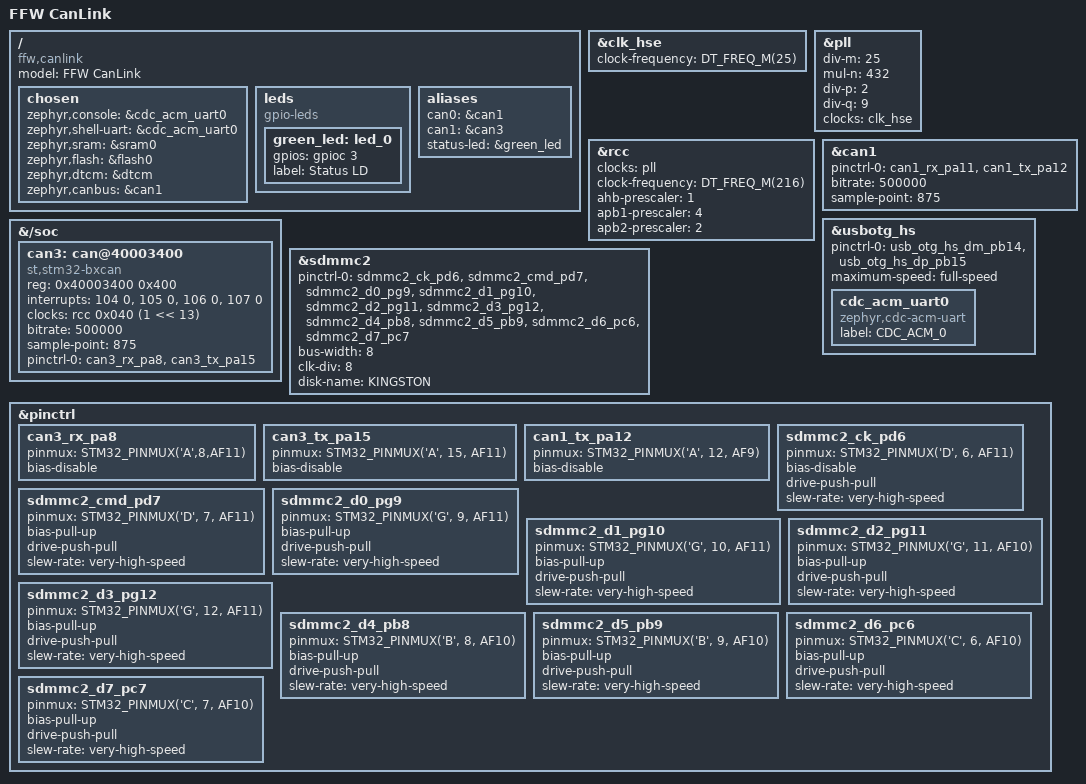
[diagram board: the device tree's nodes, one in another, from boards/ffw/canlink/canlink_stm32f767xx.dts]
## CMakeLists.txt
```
cmake_minimum_required(VERSION 3.20.0)

list(APPEND BOARD_ROOT ${CMAKE_CURRENT_SOURCE_DIR})

find_package(Zephyr REQUIRED HINTS ${ZEPHYR_BASE})
project(canlink)

target_sources(app PRIVATE
  src/duramax_build.cpp
  src/duramax_codec.cpp
  src/duramax_store.cpp
  src/duramax_validate.cpp
  src/reacher_build.cpp
  src/reacher_store.cpp
  src/reacher_codec.cpp
  src/reacher_validate.cpp
  src/main.cpp
  src/can_diagnostics.cpp
)

target_include_directories(app PRIVATE
  include
)
```

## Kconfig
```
mainmenu "CANLink"
source "Kconfig.zephyr"
menu "CANLink diagnostics"
config CANLINK_DIAGNOSTICS
    bool
    default y
    select STATS
    select CAN_STATS
    select CAN_MANUAL_RECOVERY_MODE
    select HWINFO if SOC_FAMILY_STM32
config CANLINK_EVENT_QUEUE_DEPTH
    int "ISR bus-event queue depth per bus"
    default 32
    range 4 256
config CANLINK_LOG_DEPTH
    int "Retained event records per boot per bus"
    default 64
    range 8 512
config CANLINK_TX_CONTEXTS
    int "Outstanding TX callback contexts per bus"
    default 8
    range 3 64
config CANLINK_RECOVERY_INITIAL_MS
    int "First failed recovery retry delay (ms)"
    default 100
    range 1 60000
config CANLINK_RECOVERY_MAX_MS
    int "Maximum failed recovery retry delay (ms)"
    default 5000
    range 1 600000
config CANLINK_RECOVERY_CONFIRM_MS
    int "Recovery completion observation interval (ms)"
    default 100
    range 1 60000
config CANLINK_DIAGNOSTIC_POLL_MS
    int "State/statistics reconciliation period (ms)"
    default 50
    range 1 60000
config CANLINK_RECOVERY_STACK_SIZE
    int "Recovery executor stack per bus"
    default 2048
    range 1024 16384
config CANLINK_RAW_FRAME_DEPTH
    int "Last raw RX/accepted-TX frames (0 disables)"
    default 0
    range 0 128
config CANLINK_SUPPRESS_UNHEALTHY_TX
    bool "Suppress TX before hooks while bus-off or stopped"
    default y
config CANLINK_RETAIN_DTCM
    bool "Use uncached DTCM noinit for retained banks"
    default y if SOC_SERIES_STM32F7X
    depends on DT_HAS_ARM_DTCM_ENABLED
endmenu

menu "CANLink throttle TX policy"
config CANLINK_THROTTLE_BAND_MAPPING
    bool "Apply legacy 1250/2000 RPM throttle bands"
    default y
    help
      Disable to pass the validated raw request through unchanged. Startup and
      stale-command gating still apply, including to a valid zero request.
config CANLINK_THROTTLE_STALE_TIMEOUT_ENABLE
    bool "Disable override when Reacher throttle input is stale"
    default y
config CANLINK_THROTTLE_STALE_TIMEOUT_MS
    int "Maximum age of a valid Reacher throttle command (ms)"
    default 500
    range 1 2147483647
choice CANLINK_THROTTLE_STALE_FALLBACK
    prompt "Stale throttle fallback"
    default CANLINK_THROTTLE_STALE_OVERRIDE_DISABLED
config CANLINK_THROTTLE_STALE_OVERRIDE_DISABLED
    bool "Override disabled, requested speed zero"
endchoice
endmenu
```

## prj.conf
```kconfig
CONFIG_GPIO=y
#CONFIG_SERIAL=y
CONFIG_CONSOLE=y
CONFIG_UART_CONSOLE=y
CONFIG_CPP=y
CONFIG_GLIBCXX_LIBCPP=y
CONFIG_STD_CPP23=y
CONFIG_CAN=y


CONFIG_POLL=y
CONFIG_ZBUS=y
```

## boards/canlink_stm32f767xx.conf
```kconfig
CONFIG_USB_DC_STM32_CLOCK_CHECK=n
CONFIG_SDMMC_STM32_CLOCK_CHECK=n



CONFIG_SERIAL=y
CONFIG_CONSOLE=y
CONFIG_UART_CONSOLE=y
CONFIG_STDOUT_CONSOLE=y
CONFIG_UART_LINE_CTRL=y

CONFIG_USB_DEVICE_STACK=y
CONFIG_USB_CDC_ACM=y
CONFIG_USB_DEVICE_INITIALIZE_AT_BOOT=y
CONFIG_USB_DEVICE_STACK_NEXT=n
#CONFIG_USBD_CDC_ACM_CLASS=y

#CONFIG_CDC_ACM_SERIAL_INITIALIZE_AT_BOOT=y
#CONFIG_CDC_ACM_SERIAL_PID=0x0004
#CONFIG_CDC_ACM_SERIAL_PRODUCT_STRING="CanLink USB console"

CONFIG_DEBUG_THREAD_INFO=y
CONFIG_FAULT_DUMP=2

CONFIG_INIT_STACKS=y
CONFIG_THREAD_STACK_INFO=y
CONFIG_STACK_SENTINEL=y
CONFIG_STACK_USAGE=y

CONFIG_MAIN_STACK_SIZE=32768


CONFIG_SDMMC_STM32_EMMC=y


CONFIG_MMC_STACK=y
CONFIG_DISK_ACCESS=y
CONFIG_DISK_DRIVER_SDMMC=y
CONFIG_SDMMC_STM32=y

CONFIG_FILE_SYSTEM=y
CONFIG_FAT_FILESYSTEM_ELM=y
CONFIG_FS_FATFS_LFN=y

CONFIG_LOG=y
CONFIG_PRINTK=y


CONFIG_CACHE_MANAGEMENT=y
CONFIG_DCACHE=y
# Explicit throttle defaults; set BAND_MAPPING=n for exact raw pass-through.
CONFIG_CANLINK_THROTTLE_BAND_MAPPING=y
CONFIG_CANLINK_THROTTLE_STALE_TIMEOUT_ENABLE=y
CONFIG_CANLINK_THROTTLE_STALE_TIMEOUT_MS=500
CONFIG_CANLINK_THROTTLE_STALE_OVERRIDE_DISABLED=y
```

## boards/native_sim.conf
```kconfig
CONFIG_CAN=y
CONFIG_CAN_NATIVE_LINUX=y

CONFIG_CPP=y
CONFIG_STD_CPP23=y

CONFIG_EXTERNAL_LIBC=y
CONFIG_EXTERNAL_LIBCPP=y

CONFIG_SERIAL=y
CONFIG_CONSOLE=y
CONFIG_UART_CONSOLE=y
CONFIG_PRINTK=y

CONFIG_SHELL=y
CONFIG_SHELL_BACKEND_SERIAL=y


CONFIG_POLL=y
CONFIG_DEBUG=y
CONFIG_NO_OPTIMIZATIONS=y

CONFIG_SYS_CLOCK_TICKS_PER_SEC=1000


CONFIG_MAIN_THREAD_PRIORITY=10
# Explicit throttle defaults; set BAND_MAPPING=n for exact raw pass-through.
CONFIG_CANLINK_THROTTLE_BAND_MAPPING=y
CONFIG_CANLINK_THROTTLE_STALE_TIMEOUT_ENABLE=y
CONFIG_CANLINK_THROTTLE_STALE_TIMEOUT_MS=500
CONFIG_CANLINK_THROTTLE_STALE_OVERRIDE_DISABLED=y
```

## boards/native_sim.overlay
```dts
/ {
	chosen {
		zephyr,canbus = &can0;
		zephyr,console = &uart0;
		zephyr,shell-uart = &uart0;
	};

	aliases {
		can0 = &can0;
		can1 = &can1_sim;
		status-led = &led0;
	};

	can1_sim: can1 {
		compatible = "zephyr,native-linux-can";
		status = "okay";
		host-interface = "vcan1";
		bitrate = <500000>;
		sample-point = <875>;
	};
};

&can0 {
	status = "okay";
	host-interface = "vcan0";
	bitrate = <500000>;
	sample-point = <875>;
};


&uart0 {
	status="okay";
	current-speed=<115200>;
};
```

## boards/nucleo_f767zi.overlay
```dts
&{/} {
    chosen {
        zephyr,console = &usart3;
        zephyr,shell-uart = &usart3;
        zephyr,sram = &sram0;
        zephyr,flash = &flash0;
    };

    aliases {
        can0 = &can1;
        can1 = &can3;
    };

};


&{/soc}{
    can2: can@40006800 { 

        compatible = "st,stm32-bxcan"; 

        reg = <0x40006800 0x400>; 
        interrupts = <63 0>, <64 0>, <65 0>, <66 0>; 
        interrupt-names = "TX", "RX0", "RX1", "SCE"; 
        clocks = <&rcc 0x040 (1 << 26)>; 
        status = "okay"; 
        bitrate = <500000>; 
        sample-point = <875>; 
        pinctrl-0 = <&can2_rx_pb12 &can2_tx_pb13>; 
        pinctrl-names = "default"; 
    };
    
    can3: can@40003400 {
        compatible = "st,stm32-bxcan";
        
        reg = <0x40003400 0x400>;
        interrupts = <104 0>, <105 0>, <106 0>, <107 0>;
        interrupt-names = "TX", "RX0", "RX1", "SCE";
        clocks = <&rcc 0x040 (1 << 13)>;
        status = "okay";
        bitrate = <500000>;
        sample-point = <875>;
        pinctrl-0 = <&can3_rx_pa8 &can3_tx_pa15>;
        pinctrl-names = "default";
    };


};

&can1 {
    status = "okay";
    pinctrl-0 = <&can1_rx_pa11 &can1_tx_pa12>;
    pinctrl-names = "default";
    bitrate = <500000>;
    sample-point = <875>;

};

&can3 {
    status = "okay";
    pinctrl-0 = <&can3_rx_pa8 &can3_tx_pa15>;
    pinctrl-names = "default";
};
 

&pinctrl { 
    can1_tx_pa12: can1_tx_pa12 { pinmux = <STM32_PINMUX('A', 12, AF9)>; bias-disable; };
    can2_tx_pb13: can2_tx_pb13 { pinmux = <STM32_PINMUX('B', 13, AF9)>; bias-disable; }; 
    can3_rx_pa8:  can3_rx_pa8  { pinmux = <STM32_PINMUX('A',8,AF11)>; bias-disable; };
    can3_tx_pa15: can3_tx_pa15 { pinmux = <STM32_PINMUX('A', 15, AF11)>; bias-disable; };
    can2_rx_pb12: can2_rx_pb12 { pinmux = <STM32_PINMUX('B', 12, AF9)>; bias-disable; }; 


}; 
```

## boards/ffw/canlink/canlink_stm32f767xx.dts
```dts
/dts-v1/;
#include <st/f7/stm32f767Xi.dtsi>
#include <st/f7/stm32f767zitx-pinctrl.dtsi>

/ {

    model = "FFW CanLink";
    compatible = "ffw,canlink";

    chosen {
        zephyr,console = &cdc_acm_uart0;
        zephyr,shell-uart = &cdc_acm_uart0;
        zephyr,sram = &sram0;
        zephyr,flash = &flash0;
        zephyr,dtcm = &dtcm;
        zephyr,canbus = &can1;
    };

    leds: leds {
        compatible = "gpio-leds";
        green_led: led_0 {
            gpios = <&gpioc 3 GPIO_ACTIVE_HIGH>;
            label = "Status LD";
        };
    };

    aliases {
        can0 = &can1;
        can1 = &can3;
        status-led = &green_led;
    };

};


/* now on to editing some nodes (reference zephyr/boards/st/nucleo_f767zi.dts ) */

&clk_hse {
    clock-frequency = <DT_FREQ_M(25)>;
    status = "okay";
};


&pll {
    div-m = <25>;
    mul-n = <432>;
    div-p = <2>;
    div-q = <9>;
    clocks = <&clk_hse>;
    status = "okay";
};

&rcc { 
    clocks = <&pll>;
    clock-frequency = <DT_FREQ_M(216)>;
    ahb-prescaler = <1>;
    apb1-prescaler = <4>;
    apb2-prescaler = <2>;
};

&{/soc}{
    
    can3: can@40003400 {
        compatible = "st,stm32-bxcan";
        
        reg = <0x40003400 0x400>;
        interrupts = <104 0>, <105 0>, <106 0>, <107 0>;
        interrupt-names = "TX", "RX0", "RX1", "SCE";
        clocks = <&rcc 0x040 (1 << 13)>;
        status = "okay";
        bitrate = <500000>;
        sample-point = <875>;
        pinctrl-0 = <&can3_rx_pa8 &can3_tx_pa15>;
        pinctrl-names = "default";
    };

};


&can1 {
    status = "okay";
    pinctrl-0 = <&can1_rx_pa11 &can1_tx_pa12>;
    pinctrl-names = "default";
    bitrate = <500000>;
    sample-point = <875>;

};

&can3 {
    status = "okay";
    pinctrl-0 = <&can3_rx_pa8 &can3_tx_pa15>;
    pinctrl-names = "default";
};

zephyr_udc0: &usbotg_hs {
	pinctrl-0 = <&usb_otg_hs_dm_pb14 &usb_otg_hs_dp_pb15>;
	pinctrl-names = "default";
	status = "okay";
    maximum-speed = "full-speed";

	cdc_acm_uart0: cdc_acm_uart0 {
		compatible = "zephyr,cdc-acm-uart";
        label = "CDC_ACM_0";
	};
};

&sdmmc2 {
    status = "okay";
    pinctrl-0 = <&sdmmc2_ck_pd6
                 &sdmmc2_cmd_pd7 
                 &sdmmc2_d0_pg9
                 &sdmmc2_d1_pg10
                 &sdmmc2_d2_pg11
                 &sdmmc2_d3_pg12
                 &sdmmc2_d4_pb8
                 &sdmmc2_d5_pb9
                 &sdmmc2_d6_pc6
                 &sdmmc2_d7_pc7>;
    pinctrl-names = "default";

    bus-width = <8>;
    clk-div = <8>;

    disk-name = "KINGSTON";

};

&pinctrl{

    can3_rx_pa8:  can3_rx_pa8  { pinmux = <STM32_PINMUX('A',8,AF11)>;    bias-disable; };
    can3_tx_pa15: can3_tx_pa15 { pinmux = <STM32_PINMUX('A', 15, AF11)>; bias-disable; };

    can1_tx_pa12: can1_tx_pa12 { pinmux = <STM32_PINMUX('A', 12, AF9)>;  bias-disable; };

    sdmmc2_ck_pd6: sdmmc2_ck_pd6 {
        pinmux = <STM32_PINMUX('D', 6, AF11)>;
        bias-disable;
        drive-push-pull;
        slew-rate = "very-high-speed";
    };

    sdmmc2_cmd_pd7: sdmmc2_cmd_pd7 {
        pinmux = <STM32_PINMUX('D', 7, AF11)>;
        bias-pull-up;
        drive-push-pull;
        slew-rate = "very-high-speed";
    };

    sdmmc2_d0_pg9: sdmmc2_d0_pg9 {
        pinmux = <STM32_PINMUX('G', 9, AF11)>;
        bias-pull-up;
        drive-push-pull;
        slew-rate = "very-high-speed";
    };

    sdmmc2_d1_pg10: sdmmc2_d1_pg10 {
        pinmux = <STM32_PINMUX('G', 10, AF11)>;
        bias-pull-up;
        drive-push-pull;
        slew-rate = "very-high-speed";
    };

    sdmmc2_d2_pg11: sdmmc2_d2_pg11 {
        pinmux = <STM32_PINMUX('G', 11, AF10)>;
        bias-pull-up;
        drive-push-pull;
        slew-rate = "very-high-speed";
    };

    sdmmc2_d3_pg12: sdmmc2_d3_pg12 {
        pinmux = <STM32_PINMUX('G', 12, AF11)>;
        bias-pull-up;
        drive-push-pull;
        slew-rate = "very-high-speed";
    };

    sdmmc2_d4_pb8: sdmmc2_d4_pb8 {
        pinmux = <STM32_PINMUX('B', 8, AF10)>;
        bias-pull-up;
        drive-push-pull;
        slew-rate = "very-high-speed";
    };

    sdmmc2_d5_pb9: sdmmc2_d5_pb9 {
        pinmux = <STM32_PINMUX('B', 9, AF10)>;
        bias-pull-up;
        drive-push-pull;
        slew-rate = "very-high-speed";
    };

    sdmmc2_d6_pc6: sdmmc2_d6_pc6 {
        pinmux = <STM32_PINMUX('C', 6, AF10)>;
        bias-pull-up;
        drive-push-pull;
        slew-rate = "very-high-speed";
    };

    sdmmc2_d7_pc7: sdmmc2_d7_pc7 {
        pinmux = <STM32_PINMUX('C', 7, AF10)>;
        bias-pull-up;
        drive-push-pull;
        slew-rate = "very-high-speed";
    };
};
```

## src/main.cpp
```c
#include <zephyr/device.h>
#include <zephyr/devicetree.h>
#include <zephyr/kernel.h>
#include <zephyr/sys/printk.h>
#include <zephyr/drivers/gpio.h>
#include <zephyr/drivers/uart.h>
#include <zephyr/drivers/disk.h>

#include <zephyr/usb/usb_device.h>

#include <zephyr/storage/disk_access.h>

#include <tuple>
#include <utility>
#include <string.h>

#include <zephyr/app_version.h>

#include "can_active_object.hpp"
#include "can_endpoint.hpp"

#include "duramax/duramax_db.hpp"
#include "duramax/duramax_hooks.hpp"
#include "duramax/duramax_choices.hpp"

#include "reacher/reacher_db.hpp"
#include "reacher/reacher_hooks.hpp"

#include "translator_active_object.hpp"
#include "duramax_to_reacher_signal_table.hpp"
#include "reacher_to_duramax_signal_table.hpp"
#include "message_policy_table.hpp"

namespace {
#define MY_LED_NODE DT_ALIAS(status_led)

using DuramaxAo = canfw::CanActiveObject<duramax::DuramaxDb, DuramaxHooks>;
using ReacherAo = canfw::CanActiveObject<reacher::ReacherDb, ReacherHooks>;

using DuramaxToReacherTranslator =
    Translator<
        duramax::DuramaxDb,
        reacher::ReacherDb,
        DuramaxToReacherTranslations<duramax::DuramaxDb, reacher::ReacherDb>
    >;

using ReacherToDuramaxTranslator =
    Translator<
        reacher::ReacherDb,
        duramax::DuramaxDb,
        ReacherToDuramaxTranslations<reacher::ReacherDb, duramax::DuramaxDb>
    >;

const device* const dm_bus = DEVICE_DT_GET(DT_ALIAS(can0));
const device* const reacher_bus = DEVICE_DT_GET(DT_ALIAS(can1));

static const struct gpio_dt_spec led = GPIO_DT_SPEC_GET(MY_LED_NODE, gpios);

// Stats print every Nth 100 ms iteration. Main runs at a higher priority
// than the AO threads by default (CONFIG_MAIN_THREAD_PRIORITY=0 vs 5), and
// synchronous printk spin-polls the UART, so every character printed here
// is time stolen from the 10 ms TSC1 schedule. Printing at 2 s instead of
// 100 ms cuts that starvation twentyfold; the real fix (deferred logging +
// priority inversion) is tracked for Phase 1.
constexpr std::uint8_t kStatsDivider = 20;

template <typename Endpoint, typename Msg>
void enable_periodic_checked(const Endpoint& ep,
                             const Msg& msg,
                             std::uint32_t period_ms,
                             const char* name)
{
    const int rc = ep.enable_periodic(msg, period_ms);
    if (rc != 0) {
        printk("enable_periodic(%s) failed: %d\n", name, rc);
    }
}

} // namespace

// eMMC bring-up scaffolding, kept for bench use. Not called from main():
// it never returns, which left the entire CAN path below unreachable.
int fake_main(){
    static int counter = 0;
    const char *disk = "KINGSTON";

    int rc = disk_access_ioctl(disk, DISK_IOCTL_CTRL_INIT, NULL);
    printk("disk_access_init(%s) = %d\n", disk, rc);

    uint32_t sector_count = 0;
    uint32_t sector_size = 0;

    rc = disk_access_ioctl(disk, DISK_IOCTL_GET_SECTOR_COUNT, &sector_count);
    printk("sector_count rc=%d count=%u\n", rc, sector_count);

    rc = disk_access_ioctl(disk, DISK_IOCTL_GET_SECTOR_SIZE, &sector_size);
    printk("sector_size rc=%d size=%u\n", rc, sector_size);

    __aligned(32) static uint8_t write_buf[512];
    __aligned(32) static uint8_t read_buf[512];

    if (sector_size > sizeof(write_buf)){
        printk("Sector size too large for test buffer\n");
        return -1;
    }

    // returned a value that indicates this ioctl command returned no useful data...
    // fudge...
    uint32_t erase_block_size = 0;
    rc = disk_access_ioctl(disk, DISK_IOCTL_GET_ERASE_BLOCK_SZ, &erase_block_size);
    printk("erase block size rc=%d, size=%u\n", rc, erase_block_size);


    uint32_t id = 0;
    rc = disk_access_ioctl(disk, DISK_IOCTL_GET_CARD_CID, &id);
    printk("disk cid:: rc=%d, id=%u\n", rc, id);

    memset(write_buf, 0x00, sizeof(write_buf));
    memset(read_buf, 0x00, sizeof(read_buf));

    // const char *msg = "CANLINK EMMC TEST V1";

    // memcpy(write_buf, msg, strlen(msg) + 1);

     uint32_t test_sector = 128;
    // rc = disk_access_write(disk, write_buf, test_sector, 1);

    // printk("WRITE rc=%d\n", rc);
    // if (rc){
    //     return rc;
    // }

    rc = disk_access_ioctl(disk, DISK_IOCTL_CTRL_SYNC, NULL);

    printk("SYNC rc=%d\n", rc);
    if(rc){
        return rc;
    }

    printk("about to READ\n");
    rc = disk_access_read(disk, read_buf, test_sector, 1);

    printk("READ rc=%d", rc);
    if (rc){
        return rc;
    }

    printk("READBACK: %s\n", read_buf);

    while (1) {
        k_sleep(K_SECONDS(1));
        if (counter > 5){
            printk("stuck in the loop!\n");
        }
        counter = (counter + 1) % 6;
    }
}

int main(void)
{
    const struct device *const dev = DEVICE_DT_GET(DT_CHOSEN(zephyr_console));
    if (!device_is_ready(dev)){
        printk("console not ready\n");
        return -1;
    }

    // DISABLED SECTION DUE TO KCONFIG 
    // CONFIG_USB_DEVICE_INITIALIZE_AT_BOOT=y
    // int ret = usb_enable(NULL);

    // if (ret != 0){
    //     printk("usb_enable failed: %d\n", ret);
    //     return -1;
    // }


    k_sleep(K_SECONDS(1));

    // To run the eMMC bench test instead of the CAN gateway:
    //return fake_main();

    auto duramax_result = DuramaxAo::create(dm_bus, DuramaxHooks{}, true);
    if (!duramax_result) {
        printk("DuramaxAo init failed: %d\n", static_cast<int>(duramax_result.error()));
        return -1;
    }

    auto reacher_result = ReacherAo::create(reacher_bus, ReacherHooks{}, false);
    if (!reacher_result) {
        printk("ReacherAo init failed: %d\n", static_cast<int>(reacher_result.error()));
        return -1;
    }

    auto* duramax_ao = *duramax_result;
    auto* reacher_ao = *reacher_result;

    auto duramax_ep = duramax_ao->endpoint();
    auto reacher_ep = reacher_ao->endpoint();

    if (!duramax_ep.valid() || !reacher_ep.valid()) {
        printk("Endpoint invalid\n");
        return -1;
    }

    // Seed periodic Reacher export messages.
    //
    // The k_sleep between enables is deliberate phase staggering: a freshly
    // enabled message is due immediately, and the fixed-rate scheduler then
    // holds that phase forever. Enabling all four in one command batch put
    // them on the SAME 50 ms phase, so every cycle they hit can_send at the
    // same instant -- with K_NO_WAIT mailbox acquisition, only the first
    // wins and the rest count as tx_send_failures (observed ~50/s on
    // native_sim). A few ms of offset spreads the grid points apart for good.
    {
        reacher::Export0 export0{};
        export0.eng_speed = 0;
        export0.actual_throttle = 0.0;
        export0.manifold_press = 0;
        enable_periodic_checked(reacher_ep, export0, 50, "export0");
        k_sleep(K_MSEC(2));

        reacher::Export3 export3{};
        export3.fuel_rail_pressure = 0;
        enable_periodic_checked(reacher_ep, export3, 50, "export3");
        k_sleep(K_MSEC(3));

        reacher::Export8 export8{};
        export8.battery_bus_voltage = 0.0;
        enable_periodic_checked(reacher_ep, export8, 100, "export8");
        k_sleep(K_MSEC(2));

        reacher::ExportB exportb{};
        exportb.coolant_temp = 50.0;
        exportb.oil_temp = 0.0;
        exportb.oil_pressure = 0.0;
        exportb.exhaust_gas_temp = 0.0;
        enable_periodic_checked(reacher_ep, exportb, 50, "exportb");
    }

    // Seed periodic Duramax TSC1
    {
        duramax::Tsc131 tsc1{};
        tsc1.engoverridectrlmode = 0;
        tsc1.engrequestedspeedctrlconditions = 0;
        tsc1.overridectrlmodepriority = 0;
        tsc1.engrequestedspeed_speedlimit = 0.0;
        tsc1.engrequestedtorque_torquelimit = -125;
        tsc1.tsc1transrate = std::to_underlying(
            duramax::Tsc131Tsc1transrateState::use_standard_tsc1_transmission_rates_of_10_ms_to_engine);
        tsc1.tsc1ctrlpurpose = 0;
        tsc1.engrequestedtorquehighresolution = 0;
        tsc1.messagecounter = 0;
        tsc1.messagechecksum = 0;

        if (auto ok = duramax::DuramaxDb::validate_message(tsc1); !ok) {
            printk("Initial TSC1 validation failed: signal=%u error=%u\n",
                   static_cast<unsigned>(duramax::DuramaxDb::to_index(ok.error().signal_id)),
                   static_cast<unsigned>(ok.error().error));
            return -1;
        }

        enable_periodic_checked(duramax_ep, tsc1, 10, "tsc1");
    }

    // Static storage duration is mandatory: each Translator owns two
    // SnapshotReply-sized buffers (~14 KB for the Duramax direction). As
    // function locals these overflowed the main stack; as function-local
    // statics they live in .bss and are still constructed here, after the
    // endpoints exist. -Wframe-larger-than guards against regression.
    static DuramaxToReacherTranslator duramax_to_reacher{duramax_ep, reacher_ep};
    static ReacherToDuramaxTranslator reacher_to_duramax{reacher_ep, duramax_ep};

    if (!duramax_to_reacher.valid() || !reacher_to_duramax.valid()) {
        printk("Translator invalid\n");
        return -1;
    }

    if(!gpio_is_ready_dt(&led)){
        return -1;
    }

    gpio_pin_configure_dt(&led, GPIO_OUTPUT_ACTIVE);
    static uint8_t num = 0;
    static uint8_t stats_div = 0;

    while (true) {
        duramax_to_reacher.step_once();
        reacher_to_duramax.step_once();

        if (stats_div == 0) {
            printk("D->R posted=%u val_fail=%u upd_fail=%u src_missing=%u snap_fail=%u\n",
                   duramax_to_reacher.updates_posted(),
                   duramax_to_reacher.validation_failures(),
                   duramax_to_reacher.update_failures(),
                   duramax_to_reacher.source_missing_count(),
                   duramax_to_reacher.snapshot_failures());

            printk("R->D posted=%u val_fail=%u upd_fail=%u src_missing=%u snap_fail=%u\n",
                   reacher_to_duramax.updates_posted(),
                   reacher_to_duramax.validation_failures(),
                   reacher_to_duramax.update_failures(),
                   reacher_to_duramax.source_missing_count(),
                   reacher_to_duramax.snapshot_failures());

            printk("duramax sent=%u decode_fail=%u build_fail=%u encode_fail=%u val_fail=%u send_fail=%u sched_fail=%u\n",
                   duramax_ao->tx_frames_sent(),
                   duramax_ao->decode_failures(),
                   duramax_ao->tx_build_failures(),
                   duramax_ao->tx_encode_failures(),
                   duramax_ao->tx_validation_failures(),
                   duramax_ao->tx_send_failures(),
                   duramax_ao->tx_schedule_failures());

            printk("reacher sent=%u decode_fail=%u build_fail=%u encode_fail=%u val_fail=%u send_fail=%u sched_fail=%u\n",
                   reacher_ao->tx_frames_sent(),
                   reacher_ao->decode_failures(),
                   reacher_ao->tx_build_failures(),
                   reacher_ao->tx_encode_failures(),
                   reacher_ao->tx_validation_failures(),
                   reacher_ao->tx_send_failures(),
                   reacher_ao->tx_schedule_failures());
        }
        stats_div = (stats_div + 1) % kStatsDivider;

        if(num == 0){
            gpio_pin_toggle_dt(&led);
        }
        num = (num + 1) % 17;

        k_sleep(K_MSEC(100));
    }

    return 0;
}
```

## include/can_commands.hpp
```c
#pragma once

#include <zephyr/kernel.h>

#include <cstdint>
#include <variant>
#include "throttle_policy.hpp"

namespace canfw {

enum class TxPolicy : std::uint8_t {
    send_once,
    periodic_enable,
    periodic_disable,
};

template <typename Db>
struct SnapshotReply {
    typename Db::ValueStore store{};
    throttle::Source command_source{};
    std::uint32_t rejected_throttle_inputs{};
    std::uint32_t stale_timeout_events{};
    bool valid{false};
    std::uint32_t timestamp_ms{0};
};

template <typename Db>
concept HasDbSignalPhysicalValue = requires {
    typename Db::SignalPhysicalValue;
};

template <typename Db>
using SignalPhysicalValueT = typename Db::SignalPhysicalValue;

template <typename Db>
struct TxCommand {
    using MessageId = typename Db::MessageId;
    using MessageVariant = typename Db::MessageVariant;
    using SignalId = typename Db::SignalId;
    using SignalPhysicalValue = SignalPhysicalValueT<Db>;

    struct SendMessage {
        MessageVariant message;
        TxPolicy policy{TxPolicy::periodic_enable};
        std::uint32_t period_ms_override{0};
    };

    struct UpdateSignal {
        SignalId signal_id;
        SignalPhysicalValue value;
        bool trigger_parent_send{false};
        throttle::Source source{};
    };

    struct DisableMessage {
        MessageId message_id;
    };

    struct RequestSnapshot {
        k_msgq* reply_q{nullptr};
    };

    struct RequestDiagnostics {
        k_msgq* reply_q{nullptr};
        bool previous_boot{false};
        bool clear{false};
    };

    using Variant = std::variant<
        SendMessage,
        UpdateSignal,
        DisableMessage,
        RequestSnapshot,
        RequestDiagnostics
    >;
};

} // namespace canfw
```

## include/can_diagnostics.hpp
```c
#pragma once
// Pure C++ diagnostic format and policy. No Zephyr headers or dynamic storage.
#include <array>
#include <atomic>
#include <bit>
#include <cstddef>
#include <cstdint>
#include <cstring>
#include <type_traits>

namespace canfw::diag {
enum class State : std::uint8_t { active, warning, passive, bus_off, stopped, unknown = 255 };
enum class Event : std::uint8_t {
    boot,
    transition,
    tx_rejected,
    tx_completion_error,
    recovery_attempt,
    recovery_result,
    recovery_complete,
    queue_overflow,
    rx_overflow,
    filter_failure,
    state_query_error,
    cleared,
    recovery_wait_expired
};
// Layout v1: native little-endian on both supported targets. 40 bytes, no padding.
// uptime_ms [0:8], cycles [8:12], CAN id [12:16], errno [16:20],
// arg0/arg1/aux [20:32], kind/old/new/TEC/REC/DLC/flags/reserved [32:40].
struct [[gnu::packed]] Record {
    std::uint64_t uptime_ms;
    std::uint32_t cycles, can_id;
    std::int32_t error;
    std::uint32_t arg0, arg1, aux;
    Event kind;
    State old_state, new_state;
    std::uint8_t tec, rec, dlc, flags, reserved;
};
static_assert(sizeof(Record) == 40 && offsetof(Record, kind) == 32);
static_assert(std::is_trivially_copyable_v<Record>);
static_assert(std::endian::native == std::endian::little);

template <class T, std::size_t N> struct Ring {
    static_assert(N > 0);
    std::array<T, N> entries;
    std::uint32_t head, count, overwritten;
    constexpr void push(const T &entry) {
        entries[head] = entry;
        head = (head + 1) % N;
        if (count < N)
            ++count;
        else
            ++overwritten;
    }
    constexpr const T &at(std::size_t i) const { return entries[(head + N - count + i) % N]; }
};
struct RawFrame {
    std::uint64_t uptime_ms;
    std::uint32_t id;
    std::uint8_t dlc, flags, tx, reserved;
    std::array<std::uint8_t, 8> bytes;
};
static_assert(sizeof(RawFrame) == 24);
template <std::size_t N> struct RawHistory : Ring<RawFrame, N> {};
template <> struct RawHistory<0> {};

struct Counters {
    std::array<std::uint32_t, 5> transitions;
    std::uint32_t bus_offs, recovery_attempts, recovery_successes, recovery_failures;
    std::uint32_t tx_accepted, tx_rejected, tx_completion_errors, tx_completed;
    std::uint32_t rx_frames, decode_failures, rx_drops, event_drops, tx_suppressed, filter_failures;
    std::uint32_t context_exhausted, recovery_timeouts;
    std::uint64_t last_bus_off_ms, longest_bus_off_ms, bus_off_start_ms, last_good_rx_ms,
        last_decoded_rx_ms;
    std::uint32_t episode_attempts, last_rx_id, last_tx_id;
    std::uint8_t last_rx_dlc, last_tx_dlc, entry_tec, entry_rec, exit_tec, exit_rec;
    State state;
    std::uint8_t episode_open;
};
struct DriverSnapshot {
    // stats order: bit0, bit1, stuff, CRC, form, ACK, RX overrun.
    std::array<std::uint32_t, 7> stats;
    // bxCAN order: MCR, MSR, TSR, RF0R, RF1R, IER, ESR, BTR.
    std::array<std::uint32_t, 8> registers;
    std::uint32_t core_clock_hz, capabilities, mode, configured_bitrate, sample_point;
    std::uint32_t reset_cause;
    std::int32_t state_error, core_clock_error, capabilities_error, reset_cause_error;
    std::uint8_t stats_available, registers_available, reserved[2];
};

inline constexpr auto crc_table = [] {
    std::array<std::uint32_t, 256> table{};
    for (std::uint32_t i = 0; i < 256; ++i) {
        auto c = i;
        for (int bit = 0; bit < 8; ++bit)
            c = (c >> 1) ^ ((c & 1) ? 0xEDB88320U : 0U);
        table[i] = c;
    }
    return table;
}();
constexpr std::uint32_t crc32_byte(std::uint32_t crc, std::uint8_t byte) {
    return (crc >> 8) ^ crc_table[(crc ^ byte) & 255];
}
constexpr const char *state_name(State s) {
    switch (s) {
    case State::active:
        return "ERROR_ACTIVE";
    case State::warning:
        return "ERROR_WARNING";
    case State::passive:
        return "ERROR_PASSIVE";
    case State::bus_off:
        return "BUS_OFF";
    case State::stopped:
        return "STOPPED";
    default:
        return "UNKNOWN";
    }
}
constexpr const char *event_name(Event e) {
    switch (e) {
    case Event::boot:
        return "BOOT";
    case Event::transition:
        return "STATE";
    case Event::tx_rejected:
        return "TX_REJECTED";
    case Event::tx_completion_error:
        return "TX_COMPLETION_ERROR";
    case Event::recovery_attempt:
        return "RECOVERY_ATTEMPT";
    case Event::recovery_result:
        return "RECOVERY_RESULT";
    case Event::recovery_complete:
        return "RECOVERY_COMPLETE";
    case Event::queue_overflow:
        return "EVENT_OVERFLOW";
    case Event::rx_overflow:
        return "RX_OVERFLOW";
    case Event::filter_failure:
        return "FILTER_FAILURE";
    case Event::state_query_error:
        return "STATE_QUERY_ERROR";
    case Event::cleared:
        return "CLEARED";
    case Event::recovery_wait_expired:
        return "RECOVERY_UNCONFIRMED";
    default:
        return "UNKNOWN";
    }
}
constexpr std::uint32_t crc32(const std::uint8_t *data, std::size_t len) {
    std::uint32_t c = 0xFFFFFFFFU;
    for (std::size_t i = 0; i < len; ++i)
        c = crc32_byte(c, data[i]);
    return ~c;
}
constexpr bool reached(std::uint32_t now, std::uint32_t deadline) {
    return static_cast<std::int32_t>(now - deadline) >= 0;
}
constexpr std::uint32_t until(std::uint32_t now, std::uint32_t deadline) {
    return reached(now, deadline) ? 0 : deadline - now;
}
enum class Action : std::uint8_t { none, recover, start, observe };
// One action may be in flight. A successful driver return is not recovery:
// only an observed active/warning/passive state confirms leaving bus-off.
class RecoveryPolicy {
  public:
    constexpr RecoveryPolicy(std::uint32_t initial = 100, std::uint32_t cap = 5000,
                             std::uint32_t confirmation = 100)
        : initial_(initial), cap_(cap), confirmation_(confirmation), delay_(initial) {}
    constexpr void observe(State s, std::uint32_t now) {
        if (s == state_)
            return;
        state_ = s;
        if (healthy()) {
            pending_ = false;
            delay_ = initial_;
        } else if (s == State::bus_off || s == State::stopped) {
            deadline_ = now;
            delay_ = initial_;
        }
    }
    constexpr Action due(std::uint32_t now, bool manual) {
        if (healthy() || pending_ || !reached(now, deadline_))
            return Action::none;
        if (state_ == State::unknown)
            return Action::none;
        pending_ = true;
        return state_ == State::stopped ? Action::start
                                        : (manual ? Action::recover : Action::observe);
    }
    constexpr void result(std::uint32_t now, bool success) {
        pending_ = false;
        deadline_ = now + (success && confirmation_ > delay_ ? confirmation_ : delay_);
        delay_ = delay_ > cap_ / 2 ? cap_ : delay_ * 2;
    }
    constexpr std::uint32_t wait(std::uint32_t now, std::uint32_t fallback) const {
        if (healthy() || pending_ || state_ == State::unknown)
            return fallback;
        const auto v = until(now, deadline_);
        return v < fallback ? v : fallback;
    }
    constexpr bool healthy() const {
        return state_ == State::active || state_ == State::warning || state_ == State::passive;
    }
    constexpr bool suppress() const { return state_ == State::bus_off || state_ == State::stopped; }
    constexpr State state() const { return state_; }

  private:
    std::uint32_t initial_, cap_, confirmation_, delay_, deadline_{};
    State state_{State::unknown};
    bool pending_{};
};

template <std::size_t Depth, std::size_t RawDepth = 0> struct Payload {
    Counters counters;
    DriverSnapshot driver;
    Ring<Record, Depth> events;
    [[no_unique_address]] RawHistory<RawDepth> raw;
};
template <std::size_t Depth, std::size_t RawDepth = 0> struct Bank {
    std::uint32_t magic, version, bytes, boot, sequence, crc;
    Payload<Depth, RawDepth> data;
};
template <std::size_t Depth, std::size_t RawDepth = 0> struct RetainedRegion {
    std::array<Bank<Depth, RawDepth>, 3> banks;
};
// Three banks: one previous boot is immutable; two alternate current commits.
// CRC covers header (except magic/CRC) and full payload. Torn commits retain
// the preceding valid current bank. Storage must not be zeroed by startup.
template <std::size_t Depth, std::size_t RawDepth = 0> class Journal {
  public:
    using Image = Bank<Depth, RawDepth>;
    using Region = RetainedRegion<Depth, RawDepth>;
    static constexpr std::uint32_t Magic = 0x43414E4CU, Version = 1;
    static_assert(std::is_trivially_copyable_v<Image>);
    explicit Journal(Region &region) : region_(region) {}
    static std::uint32_t checksum(const Image &b) {
        std::uint32_t c = 0xFFFFFFFFU;
        const auto *p = reinterpret_cast<const std::uint8_t *>(&b);
        for (std::size_t i = 4; i < sizeof(b); ++i)
            if (i < 20 || i >= 24)
                c = crc32_byte(c, p[i]);
        return ~c;
    }
    static bool valid(const Image &b) {
        return b.magic == Magic && b.version == Version && b.bytes == sizeof(Image) &&
               b.data.events.head < Depth && b.data.events.count <= Depth && b.crc == checksum(b);
    }
    void boot(const Record &record) {
        previous_ = -1;
        for (int i = 0; i < 3; ++i)
            if (valid(region_.banks[i])) {
                if (previous_ < 0 || newer(region_.banks[i], region_.banks[previous_]))
                    previous_ = i;
            }
        std::memset(&working_, 0, sizeof(working_));
        working_.version = Version;
        working_.bytes = sizeof(Image);
        working_.boot = previous_ < 0 ? 1 : region_.banks[previous_].boot + 1;
        working_.data.counters.state = State::unknown;
        working_.data.events.push(record);
        target_ = 0;
        commit();
    }
    void clear(const Record &record) {
        for (auto &b : region_.banks)
            b.magic = 0;
        std::atomic_thread_fence(std::memory_order_seq_cst);
        boot(record);
    }
    void commit() {
        while (target_ == previous_)
            target_ = (target_ + 1) % 3;
        auto &target = region_.banks[target_];
        ++working_.sequence;
        working_.magic = 0;
        working_.crc = checksum(working_);
        target.magic = 0;
        std::atomic_thread_fence(std::memory_order_seq_cst);
        std::memcpy(&target, &working_, sizeof(target));
        std::atomic_thread_fence(std::memory_order_seq_cst);
        target.magic = Magic;
        std::atomic_thread_fence(std::memory_order_seq_cst);
        working_.magic = Magic;
        target_ = (target_ + 1) % 3;
    }
    void append(const Record &r) { working_.data.events.push(r); }
    Payload<Depth, RawDepth> &data() { return working_.data; }
    const Image &current() const { return working_; }
    const Image &previous() const {
        static constexpr Image empty{};
        return previous_ < 0 ? empty : region_.banks[previous_];
    }

  private:
    static bool newer(const Image &a, const Image &b) {
        return a.boot == b.boot ? static_cast<std::int32_t>(a.sequence - b.sequence) > 0
                                : static_cast<std::int32_t>(a.boot - b.boot) > 0;
    }
    Region &region_;
    Image working_{};
    int previous_{-1}, target_{};
};
} // namespace canfw::diag
```

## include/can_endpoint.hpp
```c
#pragma once

#include <zephyr/kernel.h>

#include <cstdint>
#include <expected>
#include <utility>

#include "can_commands.hpp"

namespace canfw {

template <typename Db, typename Hooks>
class CanActiveObject;

enum class SnapshotError : std::uint8_t {
    post_failed,  // command queue rejected the request
    timed_out,    // no reply arrived within reply_timeout
    stale,        // a reply arrived but was not marked valid
};

template <typename Db>
class CanEndpoint {
public:
    using Command = typename TxCommand<Db>::Variant;
    using MessageId = typename Db::MessageId;
    using MessageVariant = typename Db::MessageVariant;
    using SignalId = typename Db::SignalId;
    using SignalPhysicalValue = typename Db::SignalPhysicalValue;

    constexpr CanEndpoint() = default;

    [[nodiscard]] bool valid() const {
        return tx_q_ != nullptr;
    }

    int post(const Command& cmd, k_timeout_t timeout = K_NO_WAIT) const {
        if (tx_q_ == nullptr) {
            return -EINVAL;
        }
        return k_msgq_put(tx_q_, &cmd, timeout);
    }

    int disable_message(MessageId id, k_timeout_t timeout = K_NO_WAIT) const {
        typename TxCommand<Db>::DisableMessage cmd{};
        cmd.message_id = id;
        return post(Command{cmd}, timeout);
    }

    int update_signal(SignalId signal_id,
                      SignalPhysicalValue value,
                      bool trigger_parent_send = false,
                      k_timeout_t timeout = K_NO_WAIT,
                      throttle::Source source = {}) const {
        typename TxCommand<Db>::UpdateSignal cmd{};
        cmd.signal_id = signal_id;
        cmd.value = std::move(value);
        cmd.trigger_parent_send = trigger_parent_send;
        cmd.source = source;
        return post(Command{cmd}, timeout);
    }

    int send_message(const MessageVariant& mv,
                     TxPolicy policy = TxPolicy::send_once,
                     std::uint32_t period_ms_override = 0,
                     k_timeout_t timeout = K_NO_WAIT) const {
        typename TxCommand<Db>::SendMessage cmd{};
        cmd.message = mv;
        cmd.policy = policy;
        cmd.period_ms_override = period_ms_override;
        return post(Command{cmd}, timeout);
    }

    template <typename Msg>
    int send_message(const Msg& msg,
                     TxPolicy policy = TxPolicy::send_once,
                     std::uint32_t period_ms_override = 0,
                     k_timeout_t timeout = K_NO_WAIT) const {
        return send_message(MessageVariant{msg}, policy, period_ms_override, timeout);
    }

    int enable_periodic(const MessageVariant& mv,
                        std::uint32_t period_ms_override = 0,
                        k_timeout_t timeout = K_NO_WAIT) const {
        return send_message(mv, TxPolicy::periodic_enable, period_ms_override, timeout);
    }

    template <typename Msg>
    int enable_periodic(const Msg& msg,
                        std::uint32_t period_ms_override = 0,
                        k_timeout_t timeout = K_NO_WAIT) const {
        return send_message(msg, TxPolicy::periodic_enable, period_ms_override, timeout);
    }

    // The caller owns a persistent DiagnosticClient; never use a temporary
    // reply queue whose lifetime ends before this asynchronous request.
    int request_diagnostics(k_msgq* reply_q, bool previous_boot = false,
                            bool clear = false) const {
        if (!reply_q) return -EINVAL;
        typename TxCommand<Db>::RequestDiagnostics cmd{reply_q, previous_boot, clear};
        return post(Command{cmd}, K_NO_WAIT);
    }

    int request_snapshot(k_msgq* reply_q,
                         k_timeout_t timeout = K_NO_WAIT) const {
        if (reply_q == nullptr) {
            return -EINVAL;
        }

        typename TxCommand<Db>::RequestSnapshot cmd{};
        cmd.reply_q = reply_q;
        return post(Command{cmd}, timeout);
    }

    // Blocking snapshot read into caller-owned storage.
    //
    // The SnapshotReply is ~7 KB for the larger database, so this API never
    // creates one: the reply lands directly in `out` (typically a long-lived
    // member of the caller, e.g. Translator::snapshot_buf_), and the only
    // per-call cost is the k_msgq memcpy.
    //
    // The reply queue is purged before posting so that a reply from a
    // previously timed-out request cannot be mistaken for this one -- without
    // the purge, one timeout would leave every subsequent read one snapshot
    // behind, permanently.
    [[nodiscard]] auto request_snapshot_into(k_msgq& reply_q,
                                             SnapshotReply<Db>& out,
                                             k_timeout_t post_timeout = K_NO_WAIT,
                                             k_timeout_t reply_timeout = K_MSEC(10)) const
        -> std::expected<void, SnapshotError>
    {
        k_msgq_purge(&reply_q);

        if (request_snapshot(&reply_q, post_timeout) != 0) {
            return std::unexpected{SnapshotError::post_failed};
        }

        if (k_msgq_get(&reply_q, &out, reply_timeout) != 0) {
            return std::unexpected{SnapshotError::timed_out};
        }

        if (!out.valid) {
            return std::unexpected{SnapshotError::stale};
        }

        return {};
    }

private:
    template <typename Db2, typename Hooks2>
    friend class CanActiveObject;

    explicit constexpr CanEndpoint(k_msgq* tx_q)
        : tx_q_{tx_q} {}

    k_msgq* tx_q_{nullptr};
};

} // namespace canfw
```

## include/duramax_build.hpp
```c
#pragma once

#include "duramax_metadata.hpp"
#include "duramax_store.hpp"
#include "duramax_types.hpp"

#include <expected>

namespace duramax {

enum class BuildError : std::uint8_t {
    missing_signal,
    type_mismatch,
    unsupported_message
};

auto build_eec5_electronic_engine_control_5_from_store(const ValueStore& store)
    -> std::expected<Eec5ElectronicEngineControl5, BuildError>;
auto build_eec9_electronic_engine_control_9_from_store(const ValueStore& store)
    -> std::expected<Eec9ElectronicEngineControl9, BuildError>;
auto build_ebcc_engine_exhaust_brake_cont_from_store(const ValueStore& store)
    -> std::expected<EbccEngineExhaustBrakeCont, BuildError>;
auto build_et3_engine_temperature_3_from_store(const ValueStore& store)
    -> std::expected<Et3EngineTemperature3, BuildError>;
auto build_dm21_diagnostic_readiness_2_from_store(const ValueStore& store)
    -> std::expected<Dm21DiagnosticReadiness2, BuildError>;
auto build_dm26_diagnostic_readiness_3_from_store(const ValueStore& store)
    -> std::expected<Dm26DiagnosticReadiness3, BuildError>;
auto build_ic1_intake_exhaust_cond_1_from_store(const ValueStore& store)
    -> std::expected<Ic1IntakeExhaustCond1, BuildError>;
auto build_amb_ambient_conditions_from_store(const ValueStore& store)
    -> std::expected<AmbAmbientConditions, BuildError>;
auto build_eec1_electronic_engine_control_1_from_store(const ValueStore& store)
    -> std::expected<Eec1ElectronicEngineControl1, BuildError>;
auto build_eec2_electronic_engine_control_2_from_store(const ValueStore& store)
    -> std::expected<Eec2ElectronicEngineControl2, BuildError>;
auto build_eec3_electronic_engine_control_3_from_store(const ValueStore& store)
    -> std::expected<Eec3ElectronicEngineControl3, BuildError>;
auto build_efl_p1_eng_fluid_level_press_1_from_store(const ValueStore& store)
    -> std::expected<EflP1EngFluidLevelPress1, BuildError>;
auto build_efl_p2_eng_fluid_level_press_2_from_store(const ValueStore& store)
    -> std::expected<EflP2EngFluidLevelPress2, BuildError>;
auto build_et1_engine_temperature_1_from_store(const ValueStore& store)
    -> std::expected<Et1EngineTemperature1, BuildError>;
auto build_lfe1_fuel_economy_liquid_1_from_store(const ValueStore& store)
    -> std::expected<Lfe1FuelEconomyLiquid1, BuildError>;
auto build_transportprotocol_header_from_store(const ValueStore& store)
    -> std::expected<TransportprotocolHeader, BuildError>;
auto build_transportprotocol_data_from_store(const ValueStore& store)
    -> std::expected<TransportprotocolData, BuildError>;
auto build_dm01_active_diagnostics_from_store(const ValueStore& store)
    -> std::expected<Dm01ActiveDiagnostics, BuildError>;
auto build_tsc1_31_from_store(const ValueStore& store)
    -> std::expected<Tsc131, BuildError>;
auto build_cac1_charge_air_cooler_1_from_store(const ValueStore& store)
    -> std::expected<Cac1ChargeAirCooler1, BuildError>;
auto build_hours_engine_hours_revolutions_from_store(const ValueStore& store)
    -> std::expected<HoursEngineHoursRevolutions, BuildError>;
auto build_tci5_turbocharger_information_5_from_store(const ValueStore& store)
    -> std::expected<Tci5TurbochargerInformation5, BuildError>;
auto build_vep1_vehicle_electrical_power_1_from_store(const ValueStore& store)
    -> std::expected<Vep1VehicleElectricalPower1, BuildError>;
auto build_eec20_electronic_engine_control_from_store(const ValueStore& store)
    -> std::expected<Eec20ElectronicEngineControl, BuildError>;
auto build_easi_engine_air_system_info_from_store(const ValueStore& store)
    -> std::expected<EasiEngineAirSystemInfo, BuildError>;
auto build_tsc1_03_from_store(const ValueStore& store)
    -> std::expected<Tsc103, BuildError>;
auto build_tsc1_0b_from_store(const ValueStore& store)
    -> std::expected<Tsc10b, BuildError>;
auto build_dm07_from_store(const ValueStore& store)
    -> std::expected<Dm07, BuildError>;
auto build_dm08_from_store(const ValueStore& store)
    -> std::expected<Dm08, BuildError>;
auto build_erc1_electronic_retarder_cntrl_from_store(const ValueStore& store)
    -> std::expected<Erc1ElectronicRetarderCntrl, BuildError>;
auto build_etc1_electronic_trans_cntrl_1_from_store(const ValueStore& store)
    -> std::expected<Etc1ElectronicTransCntrl1, BuildError>;
auto build_etc2_electronic_trans_cntrl_2_from_store(const ValueStore& store)
    -> std::expected<Etc2ElectronicTransCntrl2, BuildError>;
auto build_rqst_00_5e_from_store(const ValueStore& store)
    -> std::expected<Rqst005e, BuildError>;
auto build_rqst_00_21_from_store(const ValueStore& store)
    -> std::expected<Rqst0021, BuildError>;
auto build_rqst_global_5e_from_store(const ValueStore& store)
    -> std::expected<RqstGlobal5e, BuildError>;
auto build_rqst_global_03_from_store(const ValueStore& store)
    -> std::expected<RqstGlobal03, BuildError>;
auto build_tci_transfer_case_information_from_store(const ValueStore& store)
    -> std::expected<TciTransferCaseInformation, BuildError>;
auto build_trf1_transmission_fluids_1_from_store(const ValueStore& store)
    -> std::expected<Trf1TransmissionFluids1, BuildError>;
auto build_ccss_cruise_control_vehicle_spd_from_store(const ValueStore& store)
    -> std::expected<CcssCruiseControlVehicleSpd, BuildError>;
auto build_ccvs1_cruise_control_vehspd_from_store(const ValueStore& store)
    -> std::expected<Ccvs1CruiseControlVehspd, BuildError>;
auto build_ebc1_electronic_brake_cntrl_from_store(const ValueStore& store)
    -> std::expected<Ebc1ElectronicBrakeCntrl, BuildError>;
auto build_shutdn_from_store(const ValueStore& store)
    -> std::expected<Shutdn, BuildError>;

auto build_message_from_store(MessageId id, const ValueStore& store)
    -> std::expected<MessageVariant, BuildError>;

} // namespace duramax
```

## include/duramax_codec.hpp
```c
#pragma once

#include "duramax_types.hpp"

#include <cstddef>
#include <cstdint>
#include <expected>
#include <type_traits>

namespace duramax {

enum class DecodeError : std::uint8_t {
    unknown_message,
    bad_dlc,
    malformed
};

enum class EncodeError : std::uint8_t {
    buffer_too_small,
    value_out_of_range,
    unsupported_message
};

class Codec {
public:
    static auto decode(std::uint32_t can_id,
                       const std::uint8_t* data,
                       std::size_t size)
        -> std::expected<MessageVariant, DecodeError>;

    static auto encode(const MessageVariant& msg,
                       std::uint8_t* out,
                       std::size_t out_size)
        -> std::expected<std::uint8_t, EncodeError>;

    template <typename Msg>
    static auto encode(const Msg& msg,
                       std::uint8_t* out,
                       std::size_t out_size)
        -> std::expected<std::uint8_t, EncodeError>
    {
        return encode(MessageVariant{msg}, out, out_size);
    }
};

} // namespace duramax
```
